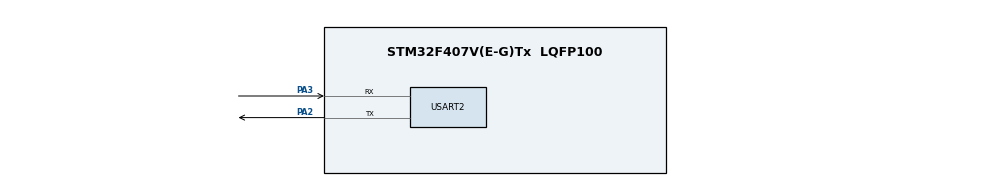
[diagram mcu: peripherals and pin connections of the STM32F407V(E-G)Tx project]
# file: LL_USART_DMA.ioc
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Dma.Request0=USART2_RX
Dma.Request1=USART2_TX
Dma.USART2_RX.0.Direction=DMA_PERIPH_TO_MEMORY
Dma.USART2_RX.0.FIFOMode=DMA_FIFOMODE_DISABLE
Dma.USART2_RX.0.Instance=DMA1_Stream5
Dma.USART2_RX.0.MemDataAlignment=DMA_MDATAALIGN_BYTE
Dma.USART2_RX.0.MemInc=DMA_MINC_ENABLE
Dma.USART2_RX.0.Mode=DMA_NORMAL
Dma.USART2_RX.0.PeriphDataAlignment=DMA_PDATAALIGN_BYTE
Dma.USART2_RX.0.PeriphInc=DMA_PINC_DISABLE
Dma.USART2_RX.0.Priority=DMA_PRIORITY_LOW
Dma.USART2_TX.1.Direction=DMA_MEMORY_TO_PERIPH
Dma.USART2_TX.1.FIFOMode=DMA_FIFOMODE_DISABLE
Dma.USART2_TX.1.Instance=DMA1_Stream6
Dma.USART2_TX.1.MemDataAlignment=DMA_MDATAALIGN_BYTE
Dma.USART2_TX.1.MemInc=DMA_MINC_ENABLE
Dma.USART2_TX.1.Mode=DMA_NORMAL
Dma.USART2_TX.1.PeriphDataAlignment=DMA_PDATAALIGN_BYTE
Dma.USART2_TX.1.PeriphInc=DMA_PINC_DISABLE
Dma.USART2_TX.1.Priority=DMA_PRIORITY_LOW
Mcu.Family=STM32F4
Mcu.Name=STM32F407V(E-G)Tx
Mcu.Package=LQFP100
NVIC.DMA1_Stream5_IRQn=true\:0\:0\:false\:false\:true\:false\:true
NVIC.DMA1_Stream6_IRQn=true\:0\:0\:false\:false\:true\:false\:true
NVIC.PriorityGroup=NVIC_PRIORITYGROUP_4
PA13.Mode=Serial_Wire
PA13.Signal=SYS_JTMS-SWDIO
PA14.Mode=Serial_Wire
PA14.Signal=SYS_JTCK-SWCLK
PA2.Mode=Asynchronous
PA2.Signal=USART2_TX
PA3.Mode=Asynchronous
PA3.Signal=USART2_RX
PH0-OSC_IN.Mode=HSE-External-Oscillator
PH0-OSC_IN.Signal=RCC_OSC_IN
PH1-OSC_OUT.Mode=HSE-External-Oscillator
PH1-OSC_OUT.Signal=RCC_OSC_OUT
ProjectManager.HeapSize=0x200
ProjectManager.StackSize=0x400
ProjectManager.TargetToolchain=STM32CubeIDE
RCC.48MHZClocksFreq_Value=84000000
RCC.AHBFreq_Value=168000000
RCC.APB1CLKDivider=RCC_HCLK_DIV4
RCC.APB1Freq_Value=42000000
RCC.APB1TimFreq_Value=84000000
RCC.APB2CLKDivider=RCC_HCLK_DIV2
RCC.APB2Freq_Value=84000000
RCC.APB2TimFreq_Value=168000000
RCC.CortexFreq_Value=168000000
RCC.HCLKFreq_Value=168000000
RCC.HSE_VALUE=8000000
RCC.HSI_VALUE=16000000
RCC.LSE_VALUE=32768
RCC.PLLM=4
RCC.PLLN=168
RCC.PLLSourceVirtual=RCC_PLLSOURCE_HSE
RCC.SYSCLKFreq_VALUE=168000000
RCC.SYSCLKSource=RCC_SYSCLKSOURCE_PLLCLK
RCC.VCOOutputFreq_Value=336000000
USART2.VirtualMode=VM_ASYNC
board=custom

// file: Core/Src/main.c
/* USER CODE BEGIN Header */
/**
  ******************************************************************************
  * @file           : main.c
  * @brief          : Main program body
  ******************************************************************************
  * @attention
  *
  * <h2><center>&copy; Copyright (c) 2021 STMicroelectronics.
  * All rights reserved.</center></h2>
  *
  * This software component is licensed by ST under BSD 3-Clause license,
  * the "License"; You may not use this file except in compliance with the
  * License. You may obtain a copy of the License at:
  *                        opensource.org/licenses/BSD-3-Clause
  *
  ******************************************************************************
  */
/* USER CODE END Header */
#include "main.h"
#include "dma.h"
#include "usart.h"
#include "gpio.h"
#include <string.h>

uint8_t fl_rx = 0, fl_tx = 0;
char tx_str[] = " The universal synchronous asynchronous receiver transmitter (USART) \r\n offers a flexible means of full-duplex data exchange \r\n";
uint8_t rx_str[256];

void SystemClock_Config(void);

int main(void)
{

  /* MCU Configuration--------------------------------------------------------*/

  /* Reset of all peripherals, Initializes the Flash interface and the Systick. */

  LL_APB2_GRP1_EnableClock(LL_APB2_GRP1_PERIPH_SYSCFG);
  LL_APB1_GRP1_EnableClock(LL_APB1_GRP1_PERIPH_PWR);

  NVIC_SetPriorityGrouping(NVIC_PRIORITYGROUP_4);

  /* System interrupt init*/

  /* Configure the system clock */
  SystemClock_Config();

  /* Initialize all configured peripherals */
  MX_GPIO_Init();
  MX_DMA_Init();
  MX_USART2_UART_Init();
  /* USER CODE BEGIN 2 */
  LL_DMA_DisableStream(DMA1, LL_DMA_STREAM_5); //Прежде чем настраивать каналы их необходимо отключить - ОБЯЗАТЕЛЬНО
  LL_DMA_DisableStream(DMA1, LL_DMA_STREAM_6);
  //
  LL_DMA_ClearFlag_TC5(DMA1); //Очищаем флаги - это ОБЯЗАТЕЛЬНО
  LL_DMA_ClearFlag_TE5(DMA1);
  LL_DMA_ClearFlag_TC6(DMA1);
  LL_DMA_ClearFlag_TE6(DMA1);
  //
  LL_USART_EnableDMAReq_RX(USART2); //Даем добро на запрос DMA USART2 (передача и прием)
  LL_USART_EnableDMAReq_TX(USART2);
  //
  LL_DMA_EnableIT_TC(DMA1, LL_DMA_STREAM_5);
  LL_DMA_EnableIT_TE(DMA1, LL_DMA_STREAM_5);
  LL_DMA_EnableIT_TC(DMA1, LL_DMA_STREAM_6);
  LL_DMA_EnableIT_TE(DMA1, LL_DMA_STREAM_6);
  //
  //LL_DMA_ClearFlag_GI5(DMA1);
  //LL_DMA_ClearFlag_GI6(DMA1);
  LL_DMA_ClearFlag_TC5(DMA1); //Очищаем флаги - это ОБЯЗАТЕЛЬНО
  LL_DMA_ClearFlag_TE5(DMA1);
  LL_DMA_ClearFlag_TC6(DMA1);
  LL_DMA_ClearFlag_TE6(DMA1);
  //
  LL_DMA_ConfigAddresses(DMA1, LL_DMA_STREAM_5, LL_USART_DMA_GetRegAddr(USART2), (uint32_t)&rx_str, LL_DMA_GetDataTransferDirection(DMA1, LL_DMA_STREAM_5));
  LL_DMA_ConfigAddresses(DMA1, LL_DMA_STREAM_6, (uint32_t)&tx_str, LL_USART_DMA_GetRegAddr(USART2), LL_DMA_GetDataTransferDirection(DMA1, LL_DMA_STREAM_6));
  /* USER CODE END 2 */

  /* Infinite loop */
  while (1)
  {
	  USART_BufferRecieve(rx_str, 256);
	  USART_BufferTransmit((uint8_t *)tx_str, strlen(tx_str));
  }
}

void SystemClock_Config(void)
{
  LL_FLASH_SetLatency(LL_FLASH_LATENCY_5);
  while(LL_FLASH_GetLatency()!= LL_FLASH_LATENCY_5)
  {
  }
  LL_PWR_SetRegulVoltageScaling(LL_PWR_REGU_VOLTAGE_SCALE1);
  LL_RCC_HSE_Enable();

   /* Wait till HSE is ready */
  while(LL_RCC_HSE_IsReady() != 1)
  {

  }
  LL_RCC_PLL_ConfigDomain_SYS(LL_RCC_PLLSOURCE_HSE, LL_RCC_PLLM_DIV_4, 168, LL_RCC_PLLP_DIV_2);
  LL_RCC_PLL_Enable();

   /* Wait till PLL is ready */
  while(LL_RCC_PLL_IsReady() != 1)
  {

  }
  LL_RCC_SetAHBPrescaler(LL_RCC_SYSCLK_DIV_1);
  LL_RCC_SetAPB1Prescaler(LL_RCC_APB1_DIV_4);
  LL_RCC_SetAPB2Prescaler(LL_RCC_APB2_DIV_2);
  LL_RCC_SetSysClkSource(LL_RCC_SYS_CLKSOURCE_PLL);

   /* Wait till System clock is ready */
  while(LL_RCC_GetSysClkSource() != LL_RCC_SYS_CLKSOURCE_STATUS_PLL)
  {

  }
  LL_Init1msTick(168000000);
  LL_SetSystemCoreClock(168000000);
}

void Error_Handler(void)
{
}

/************************ (C) COPYRIGHT STMicroelectronics *****END OF FILE****/
